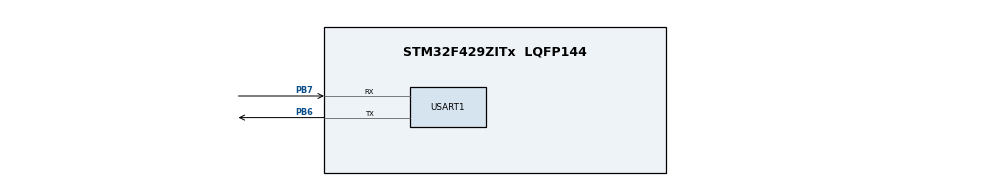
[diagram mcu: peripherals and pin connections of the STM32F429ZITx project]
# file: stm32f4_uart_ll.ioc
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Dma.Request0=USART1_RX
Dma.Request1=USART1_TX
Dma.USART1_RX.0.Direction=DMA_PERIPH_TO_MEMORY
Dma.USART1_RX.0.FIFOMode=DMA_FIFOMODE_DISABLE
Dma.USART1_RX.0.Instance=DMA2_Stream2
Dma.USART1_RX.0.MemDataAlignment=DMA_MDATAALIGN_BYTE
Dma.USART1_RX.0.MemInc=DMA_MINC_ENABLE
Dma.USART1_RX.0.Mode=DMA_NORMAL
Dma.USART1_RX.0.PeriphDataAlignment=DMA_PDATAALIGN_BYTE
Dma.USART1_RX.0.PeriphInc=DMA_PINC_DISABLE
Dma.USART1_RX.0.Priority=DMA_PRIORITY_LOW
Dma.USART1_TX.1.Direction=DMA_MEMORY_TO_PERIPH
Dma.USART1_TX.1.FIFOMode=DMA_FIFOMODE_DISABLE
Dma.USART1_TX.1.Instance=DMA2_Stream7
Dma.USART1_TX.1.MemDataAlignment=DMA_MDATAALIGN_BYTE
Dma.USART1_TX.1.MemInc=DMA_MINC_ENABLE
Dma.USART1_TX.1.Mode=DMA_NORMAL
Dma.USART1_TX.1.PeriphDataAlignment=DMA_PDATAALIGN_BYTE
Dma.USART1_TX.1.PeriphInc=DMA_PINC_DISABLE
Dma.USART1_TX.1.Priority=DMA_PRIORITY_LOW
Mcu.Family=STM32F4
Mcu.Name=STM32F429ZITx
Mcu.Package=LQFP144
NVIC.DMA2_Stream2_IRQn=true\:0\:0\:false\:false\:true\:false\:true
NVIC.DMA2_Stream7_IRQn=true\:0\:0\:false\:false\:true\:false\:true
NVIC.PriorityGroup=NVIC_PRIORITYGROUP_4
PA13.Mode=Trace_Asynchronous_SW
PA13.Signal=SYS_JTMS-SWDIO
PA14.Mode=Trace_Asynchronous_SW
PA14.Signal=SYS_JTCK-SWCLK
PB3.Mode=Trace_Asynchronous_SW
PB3.Signal=SYS_JTDO-SWO
PB6.Mode=Asynchronous
PB6.Signal=USART1_TX
PB7.Mode=Asynchronous
PB7.Signal=USART1_RX
PC14/OSC32_IN.Mode=LSE-External-Oscillator
PC14/OSC32_IN.Signal=RCC_OSC32_IN
PC15/OSC32_OUT.Mode=LSE-External-Oscillator
PC15/OSC32_OUT.Signal=RCC_OSC32_OUT
PH0/OSC_IN.Mode=HSE-External-Oscillator
PH0/OSC_IN.Signal=RCC_OSC_IN
PH1/OSC_OUT.Mode=HSE-External-Oscillator
PH1/OSC_OUT.Signal=RCC_OSC_OUT
ProjectManager.HeapSize=0x200
ProjectManager.StackSize=0x400
ProjectManager.TargetToolchain=SW4STM32
RCC.48MHZClocksFreq_Value=90000000
RCC.AHBFreq_Value=180000000
RCC.APB1CLKDivider=RCC_HCLK_DIV4
RCC.APB1Freq_Value=45000000
RCC.APB1TimFreq_Value=90000000
RCC.APB2CLKDivider=RCC_HCLK_DIV2
RCC.APB2Freq_Value=90000000
RCC.APB2TimFreq_Value=180000000
RCC.CortexFreq_Value=180000000
RCC.HCLKFreq_Value=180000000
RCC.HSE_VALUE=25000000
RCC.HSI_VALUE=16000000
RCC.PLLM=15
RCC.PLLN=216
RCC.PLLSourceVirtual=RCC_PLLSOURCE_HSE
RCC.SYSCLKFreq_VALUE=180000000
RCC.SYSCLKSource=RCC_SYSCLKSOURCE_PLLCLK
RCC.VCOOutputFreq_Value=360000000
USART1.VirtualMode=VM_ASYNC
board=custom

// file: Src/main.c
/* USER CODE BEGIN Header */
/**
  ******************************************************************************
  * @file           : main.c
  * @brief          : Main program body
  ******************************************************************************
  * @attention
  *
  * <h2><center>&copy; Copyright (c) 2019 STMicroelectronics.
  * All rights reserved.</center></h2>
  *
  * This software component is licensed by ST under BSD 3-Clause license,
  * the "License"; You may not use this file except in compliance with the
  * License. You may obtain a copy of the License at:
  *                        opensource.org/licenses/BSD-3-Clause
  *
  ******************************************************************************
  */
/* USER CODE END Header */

#include "main.h"

/* USER CODE BEGIN Includes */
#include "string.h"
#include "UART_LL.h"
/* USER CODE END Includes */

/* USER CODE BEGIN PV */
static uint8_t testTxBuff[] = "nadawanie test test\r\n";
/* USER CODE END PV */

void SystemClock_Config(void);
static void MX_GPIO_Init(void);
static void MX_DMA_Init(void);
static void MX_USART1_UART_Init(void);

/* USER CODE BEGIN 0 */
//-----------------------------------------
//--------------------------------------------------------

//--------------------------------------------------------

//---------------------------------------------------------
/* USER CODE END 0 */

int main(void)
{

  /* MCU Configuration--------------------------------------------------------*/

  /* Reset of all peripherals, Initializes the Flash interface and the Systick. */

  LL_APB2_GRP1_EnableClock(LL_APB2_GRP1_PERIPH_SYSCFG);
  LL_APB1_GRP1_EnableClock(LL_APB1_GRP1_PERIPH_PWR);

  NVIC_SetPriorityGrouping(NVIC_PRIORITYGROUP_4);

  /* System interrupt init*/

  /* Configure the system clock */
  SystemClock_Config();

  /* Initialize all configured peripherals */
  MX_GPIO_Init();
  MX_DMA_Init();
  MX_USART1_UART_Init();
  /* USER CODE BEGIN 2 */
  LL_DMA_DisableStream(DMA2, LL_DMA_STREAM_2);
  LL_DMA_DisableStream(DMA2, LL_DMA_STREAM_7);
  LL_DMA_ClearFlag_TC2(DMA2);
  LL_DMA_ClearFlag_TE2(DMA2);
  LL_DMA_ClearFlag_TC7(DMA2);
  LL_DMA_ClearFlag_TE7(DMA2);
  LL_USART_EnableDMAReq_RX(USART1);
  LL_USART_EnableDMAReq_TX(USART1);
  LL_DMA_EnableIT_TC(DMA2, LL_DMA_STREAM_2);
  LL_DMA_EnableIT_TE(DMA2, LL_DMA_STREAM_2);
  LL_DMA_EnableIT_TC(DMA2, LL_DMA_STREAM_7);
  LL_DMA_EnableIT_TE(DMA2, LL_DMA_STREAM_7);
  LL_DMA_ClearFlag_TC2(DMA2);
  LL_DMA_ClearFlag_TE2(DMA2);
  LL_DMA_ClearFlag_TC7(DMA2);
  LL_DMA_ClearFlag_TE7(DMA2);
  LL_DMA_ConfigAddresses(DMA2, LL_DMA_STREAM_2,
						  LL_USART_DMA_GetRegAddr(USART1),
						  (uint32_t)&DMAUart_Struct.dmaReceiveData,
						  LL_DMA_GetDataTransferDirection(DMA2, LL_DMA_STREAM_2));
  LL_DMA_ConfigAddresses(DMA2, LL_DMA_STREAM_7,
		  (uint32_t)&DMAUart_Struct.dmaReceiveData,
		  LL_USART_DMA_GetRegAddr(USART1),
		  LL_DMA_GetDataTransferDirection(DMA2, LL_DMA_STREAM_7));

  LL_DMA_DisableStream(DMA2, LL_DMA_STREAM_7);
  LL_DMA_ConfigAddresses(DMA2, LL_DMA_STREAM_7,
 		  (uint32_t)&testTxBuff,
 		  LL_USART_DMA_GetRegAddr(USART1),
 		  LL_DMA_GetDataTransferDirection(DMA2, LL_DMA_STREAM_7));
   USART_Transmit_WaitUntillFinished(sizeof(testTxBuff) - 1);

   LL_DMA_ConfigAddresses(DMA2, LL_DMA_STREAM_7,
 		  (uint32_t)&DMAUart_Struct.dmaReceiveData,
 		  LL_USART_DMA_GetRegAddr(USART1),
 		  LL_DMA_GetDataTransferDirection(DMA2, LL_DMA_STREAM_7));

  UART_DMA_EnableReceive(1);

  /* USER CODE END 2 */

  /* Infinite loop */
  while (1)
  {
	  //USART_RX(1);
  }
}

void SystemClock_Config(void)
{
  LL_FLASH_SetLatency(LL_FLASH_LATENCY_5);

  if(LL_FLASH_GetLatency() != LL_FLASH_LATENCY_5)
  {
  Error_Handler();
  }
  LL_PWR_SetRegulVoltageScaling(LL_PWR_REGU_VOLTAGE_SCALE1);
  LL_PWR_EnableOverDriveMode();
  LL_RCC_HSE_Enable();

   /* Wait till HSE is ready */
  while(LL_RCC_HSE_IsReady() != 1)
  {

  }
  LL_RCC_PLL_ConfigDomain_SYS(LL_RCC_PLLSOURCE_HSE, LL_RCC_PLLM_DIV_15, 216, LL_RCC_PLLP_DIV_2);
  LL_RCC_PLL_Enable();

   /* Wait till PLL is ready */
  while(LL_RCC_PLL_IsReady() != 1)
  {

  }
  LL_RCC_SetAHBPrescaler(LL_RCC_SYSCLK_DIV_1);
  LL_RCC_SetAPB1Prescaler(LL_RCC_APB1_DIV_4);
  LL_RCC_SetAPB2Prescaler(LL_RCC_APB2_DIV_2);
  LL_RCC_SetSysClkSource(LL_RCC_SYS_CLKSOURCE_PLL);

   /* Wait till System clock is ready */
  while(LL_RCC_GetSysClkSource() != LL_RCC_SYS_CLKSOURCE_STATUS_PLL)
  {

  }
  LL_Init1msTick(180000000);
  LL_SYSTICK_SetClkSource(LL_SYSTICK_CLKSOURCE_HCLK);
  LL_SetSystemCoreClock(180000000);
  LL_RCC_SetTIMPrescaler(LL_RCC_TIM_PRESCALER_TWICE);
}

static void MX_USART1_UART_Init(void)
{

  LL_USART_InitTypeDef USART_InitStruct = {0};

  LL_GPIO_InitTypeDef GPIO_InitStruct = {0};

  /* Peripheral clock enable */
  LL_APB2_GRP1_EnableClock(LL_APB2_GRP1_PERIPH_USART1);

  LL_AHB1_GRP1_EnableClock(LL_AHB1_GRP1_PERIPH_GPIOB);
  /**USART1 GPIO Configuration
  PB6   ------> USART1_TX
  PB7   ------> USART1_RX
  */
  GPIO_InitStruct.Pin = LL_GPIO_PIN_6|LL_GPIO_PIN_7;
  GPIO_InitStruct.Mode = LL_GPIO_MODE_ALTERNATE;
  GPIO_InitStruct.Speed = LL_GPIO_SPEED_FREQ_VERY_HIGH;
  GPIO_InitStruct.OutputType = LL_GPIO_OUTPUT_PUSHPULL;
  GPIO_InitStruct.Pull = LL_GPIO_PULL_UP;
  GPIO_InitStruct.Alternate = LL_GPIO_AF_7;
  LL_GPIO_Init(GPIOB, &GPIO_InitStruct);

  /* USART1 DMA Init */

  /* USART1_RX Init */
  LL_DMA_SetChannelSelection(DMA2, LL_DMA_STREAM_2, LL_DMA_CHANNEL_4);

  LL_DMA_SetDataTransferDirection(DMA2, LL_DMA_STREAM_2, LL_DMA_DIRECTION_PERIPH_TO_MEMORY);

  LL_DMA_SetStreamPriorityLevel(DMA2, LL_DMA_STREAM_2, LL_DMA_PRIORITY_LOW);

  LL_DMA_SetMode(DMA2, LL_DMA_STREAM_2, LL_DMA_MODE_NORMAL);

  LL_DMA_SetPeriphIncMode(DMA2, LL_DMA_STREAM_2, LL_DMA_PERIPH_NOINCREMENT);

  LL_DMA_SetMemoryIncMode(DMA2, LL_DMA_STREAM_2, LL_DMA_MEMORY_INCREMENT);

  LL_DMA_SetPeriphSize(DMA2, LL_DMA_STREAM_2, LL_DMA_PDATAALIGN_BYTE);

  LL_DMA_SetMemorySize(DMA2, LL_DMA_STREAM_2, LL_DMA_MDATAALIGN_BYTE);

  LL_DMA_DisableFifoMode(DMA2, LL_DMA_STREAM_2);

  /* USART1_TX Init */
  LL_DMA_SetChannelSelection(DMA2, LL_DMA_STREAM_7, LL_DMA_CHANNEL_4);

  LL_DMA_SetDataTransferDirection(DMA2, LL_DMA_STREAM_7, LL_DMA_DIRECTION_MEMORY_TO_PERIPH);

  LL_DMA_SetStreamPriorityLevel(DMA2, LL_DMA_STREAM_7, LL_DMA_PRIORITY_LOW);

  LL_DMA_SetMode(DMA2, LL_DMA_STREAM_7, LL_DMA_MODE_NORMAL);

  LL_DMA_SetPeriphIncMode(DMA2, LL_DMA_STREAM_7, LL_DMA_PERIPH_NOINCREMENT);

  LL_DMA_SetMemoryIncMode(DMA2, LL_DMA_STREAM_7, LL_DMA_MEMORY_INCREMENT);

  LL_DMA_SetPeriphSize(DMA2, LL_DMA_STREAM_7, LL_DMA_PDATAALIGN_BYTE);

  LL_DMA_SetMemorySize(DMA2, LL_DMA_STREAM_7, LL_DMA_MDATAALIGN_BYTE);

  LL_DMA_DisableFifoMode(DMA2, LL_DMA_STREAM_7);

  USART_InitStruct.BaudRate = 115200;
  USART_InitStruct.DataWidth = LL_USART_DATAWIDTH_8B;
  USART_InitStruct.StopBits = LL_USART_STOPBITS_1;
  USART_InitStruct.Parity = LL_USART_PARITY_NONE;
  USART_InitStruct.TransferDirection = LL_USART_DIRECTION_TX_RX;
  USART_InitStruct.HardwareFlowControl = LL_USART_HWCONTROL_NONE;
  USART_InitStruct.OverSampling = LL_USART_OVERSAMPLING_16;
  LL_USART_Init(USART1, &USART_InitStruct);
  LL_USART_ConfigAsyncMode(USART1);
  LL_USART_Enable(USART1);

}

static void MX_DMA_Init(void)
{
  /* Init with LL driver */
  /* DMA controller clock enable */
  LL_AHB1_GRP1_EnableClock(LL_AHB1_GRP1_PERIPH_DMA2);

  /* DMA interrupt init */
  /* DMA2_Stream2_IRQn interrupt configuration */
  NVIC_SetPriority(DMA2_Stream2_IRQn, NVIC_EncodePriority(NVIC_GetPriorityGrouping(),0, 0));
  NVIC_EnableIRQ(DMA2_Stream2_IRQn);
  /* DMA2_Stream7_IRQn interrupt configuration */
  NVIC_SetPriority(DMA2_Stream7_IRQn, NVIC_EncodePriority(NVIC_GetPriorityGrouping(),0, 0));
  NVIC_EnableIRQ(DMA2_Stream7_IRQn);

}

static void MX_GPIO_Init(void)
{

  /* GPIO Ports Clock Enable */
  LL_AHB1_GRP1_EnableClock(LL_AHB1_GRP1_PERIPH_GPIOC);
  LL_AHB1_GRP1_EnableClock(LL_AHB1_GRP1_PERIPH_GPIOH);
  LL_AHB1_GRP1_EnableClock(LL_AHB1_GRP1_PERIPH_GPIOA);
  LL_AHB1_GRP1_EnableClock(LL_AHB1_GRP1_PERIPH_GPIOB);

}

void Error_Handler(void)
{
}

/************************ (C) COPYRIGHT STMicroelectronics *****END OF FILE****/
